VERSION ""

NS_ :

BS_:

BU_: DI BMS ESP DAS SCCM GTW

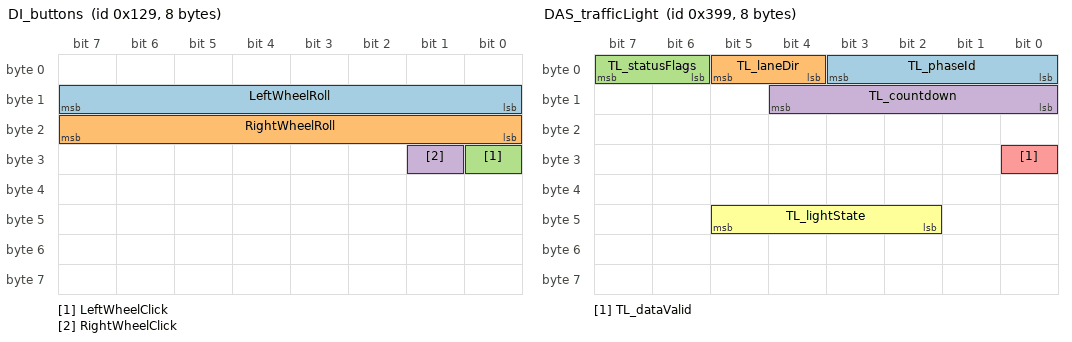
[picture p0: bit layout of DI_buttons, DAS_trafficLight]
BO_ 297 DI_buttons: 8 DI
 SG_ LeftWheelRoll : 8|8@1+ (1,0) [0|255] "steps" DI
 SG_ RightWheelRoll : 16|8@1+ (1,0) [0|255] "steps" DI
 SG_ LeftWheelClick : 24|1@1+ (1,0) [0|1] "" DI
 SG_ RightWheelClick : 25|1@1+ (1,0) [0|1] "" DI

BO_ 921 DAS_trafficLight: 8 DAS
 SG_ TL_phaseId : 0|4@1+ (1,0) [0|15] "" DAS
 SG_ TL_laneDir : 4|2@1+ (1,0) [0|3] "" DAS
 SG_ TL_statusFlags : 6|2@1+ (1,0) [0|3] "" DAS
 SG_ TL_countdown : 8|5@1+ (1,0) [0|31] "s" DAS
 SG_ TL_dataValid : 24|1@1+ (1,0) [0|1] "" DAS
 SG_ TL_lightState : 42|4@1+ (1,0) [0|15] "" DAS

VAL_ 921 TL_lightState 0 "Unknown" 1 "Red" 2 "Yellow" 3 "Yellow" 4 "Flashing" 7 "Green" ;

BO_ 925 DAS_stopLine: 8 DAS
 SG_ SL_distStatus : 16|2@1+ (1,0) [0|3] "" DAS
 SG_ SL_distance : 21|12@1+ (0.1,0) [0|409.5] "m" DAS
